VERSION ""

NS_ :

BS_:

BU_:

BO_ 2148139008 VDM_GPS_LAT_LONG: 8 Vector__XXX
 SG_ VDM_GPS_Latitude : 7|32@0- (1,0) [0|0] "deg" Vector__XXX
 SG_ VDM_GPS_Longitude : 39|32@0- (1,0) [0|0] "deg" Vector__XXX

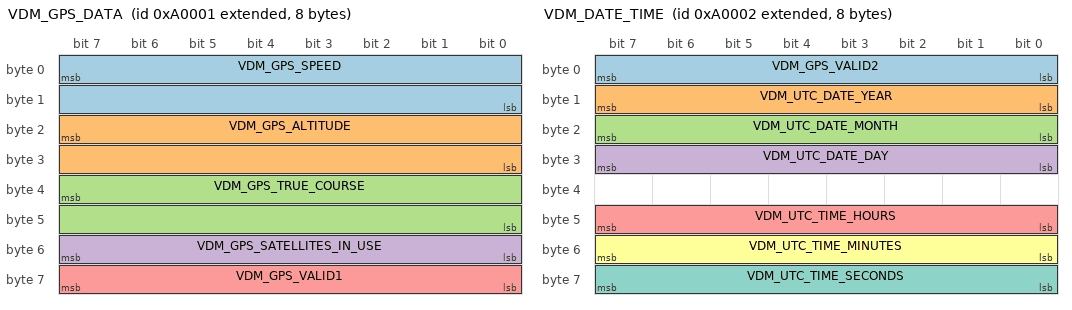
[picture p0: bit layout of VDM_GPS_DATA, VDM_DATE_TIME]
BO_ 2148139009 VDM_GPS_DATA: 8 Vector__XXX
 SG_ VDM_GPS_SPEED : 7|16@0+ (0.01,0) [0|0] "mph" Vector__XXX
 SG_ VDM_GPS_ALTITUDE : 23|16@0- (1,0) [0|0] "ft" Vector__XXX
 SG_ VDM_GPS_TRUE_COURSE : 39|16@0+ (0.01,0) [0|0] "deg" Vector__XXX
 SG_ VDM_GPS_SATELLITES_IN_USE : 55|8@0+ (1,0) [0|0] "" Vector__XXX
 SG_ VDM_GPS_VALID1 : 63|8@0+ (1,0) [0|0] "" Vector__XXX

BO_ 2148139010 VDM_DATE_TIME: 8 Vector__XXX
 SG_ VDM_GPS_VALID2 : 7|8@0+ (1,0) [0|0] "" Vector__XXX
 SG_ VDM_UTC_DATE_YEAR : 15|8@0+ (1,0) [0|0] "years" Vector__XXX
 SG_ VDM_UTC_DATE_MONTH : 23|8@0+ (1,0) [0|0] "months" Vector__XXX
 SG_ VDM_UTC_DATE_DAY : 31|8@0+ (1,0) [0|0] "days" Vector__XXX
 SG_ VDM_UTC_TIME_HOURS : 47|8@0+ (1,0) [0|0] "hours" Vector__XXX
 SG_ VDM_UTC_TIME_MINUTES : 55|8@0+ (1,0) [0|0] "minutes" Vector__XXX
 SG_ VDM_UTC_TIME_SECONDS : 63|8@0+ (1,0) [0|0] "seconds" Vector__XXX

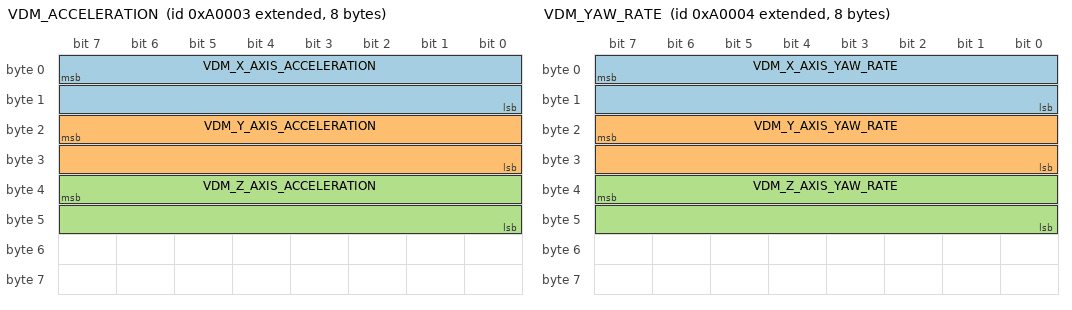
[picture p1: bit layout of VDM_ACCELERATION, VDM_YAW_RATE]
BO_ 2148139011 VDM_ACCELERATION: 8 Vector__XXX
 SG_ VDM_X_AXIS_ACCELERATION : 7|16@0- (0.000244141,0) [0|0] "gs" Vector__XXX
 SG_ VDM_Y_AXIS_ACCELERATION : 23|16@0- (0.000244141,0) [0|0] "gs" Vector__XXX
 SG_ VDM_Z_AXIS_ACCELERATION : 39|16@0- (0.000244141,0) [0|0] "gs" Vector__XXX

BO_ 2148139012 VDM_YAW_RATE: 8 Vector__XXX
 SG_ VDM_X_AXIS_YAW_RATE : 7|16@0- (0.015258789,0) [0|0] "deg/s" Vector__XXX
 SG_ VDM_Y_AXIS_YAW_RATE : 23|16@0- (0.015258789,0) [0|0] "deg/s" Vector__XXX
 SG_ VDM_Z_AXIS_YAW_RATE : 39|16@0- (0.015258789,0) [0|0] "deg/s" Vector__XXX

BA_DEF_  "BusType" STRING ;
BA_DEF_DEF_  "BusType" "CAN";
SIG_VALTYPE_ 2148139008 VDM_GPS_Latitude : 1;
SIG_VALTYPE_ 2148139008 VDM_GPS_Longitude : 1;
